# Template register map
Vendor: VendorName Co.Ltd; Series: SeriesName; File version: 1.2
CPU: CM7 r0p1, little endian, MPU, FPU, 4 interrupt priority bits
Registers are 32-bit, read-write, no defined reset value unless marked. A register's access mark holds for its fields unless they carry their own. Offsets are from the block's base; [hi:lo] are bit positions; lines under a group give offsets from that group; {n}, {i} and the like mark numbered series.

## CANFD1 — Controller Area Network FD 1
Base 0x40084000
Same registers: CANFD2 0x4009C000
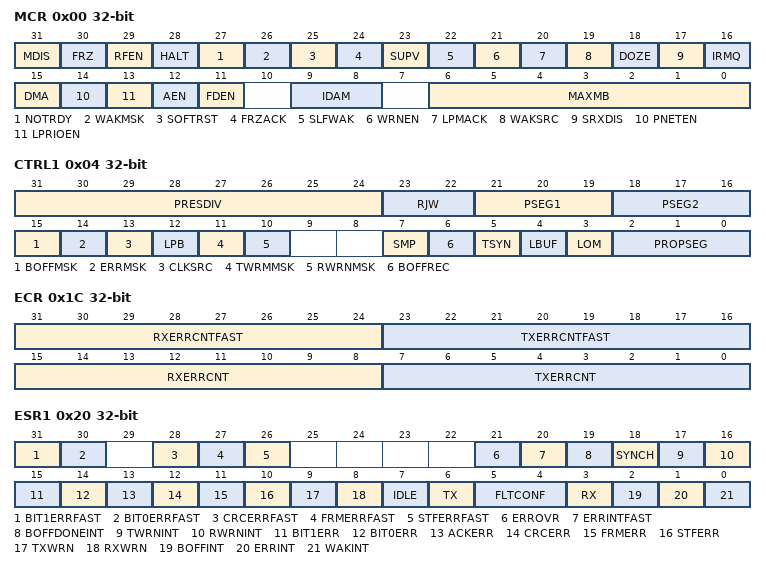
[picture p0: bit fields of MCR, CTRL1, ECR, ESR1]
0x00 MCR — CAN module config register
  [31] MDIS — CANFD MDIS bit: module disable
  [30] FRZ — CANFD FRZ bit: freeze enable
  [29] RFEN — CANFD RFEN bit: Rx FIFO enable
  [28] HALT — CANFD HALT bit: halt FlexCAN
  [27] NOTRDY — CANFD NOTRDY bit: FlexCAN not ready
  [26] WAKMSK — CANFD WAKMSK bit: wake up interrupt mask
  [25] SOFTRST — CANFD SOFTRST bit: soft reset
  [24] FRZACK ro — CANFD FRZACK bit: freeze mode acknowledge
  [23] SUPV — CANFD SUPV bit: supervisor mode
  [22] SLFWAK — CANFD SLFWAK bit: self wake up
  [21] WRNEN — CANFD WRNEN bit: warning interrupt enable
  [20] LPMACK — CANFD LPMACK bit: low-power mode acknowledge
  [19] WAKSRC — CANFD WAKSRC bit: wake up source
  [18] DOZE — CANFD DOZE bit: doze mode enable
  [17] SRXDIS — CANFD SRXDIS bit: self reception disable
  [16] IRMQ — CANFD IRMQ bit: individual Rx masking And queue enable
  [15] DMA — CANFD DMA bit: DMA enable
  [14] PNETEN — CANFD PNETEN bit: pretended networking enable
  [13] LPRIOEN — CANFD LPRIOEN bit: local priority enable
  [12] AEN — CANFD AEN bit: abort enable
  [11] FDEN — CANFD FDEN bit: CAN FD operation enable
  [9:8] IDAM — CANFD IDAM[1:0] bit: ID acceptance mode
  [6:0] MAXMB — CANFD MAXMB[6:0] bit: number of the last message buffer
0x04 CTRL1 — CAN control register 1
  [31:24] PRESDIV — CANFD PRESDIV[7:0] bit: prescaler division factor
  [23:22] RJW — CANFD RJW[1:0] bit: resync jump width
  [21:19] PSEG1 — CANFD PSEG1[2:0] bit: phase segment 1
  [18:16] PSEG2 — CANFD PSEG2[2:0] bit: phase segment 2
  [15] BOFFMSK — CANFD BOFFMSK bit: bus off interrtupt mask
  [14] ERRMSK — CANFD ERRMSK bit: error interrupt mask
  [13] CLKSRC — CANFD CLKSRC bit: CAN engine clock source
  [12] LPB — CANFD LPB bit: loop-back mode
  [11] TWRMMSK — CANFD TWRMMSK bit: Tx warning inrerrupt mask
  [10] RWRNMSK — CANFD RWRNMSK bit: Rx warn inrerrupt mask
  [7] SMP — CANFD SMP bit: CAN bit sampling
  [6] BOFFREC — CANFD BOFFREC bit: bus off recovery
  [5] TSYN — CANFD TSYN bit: timer sync
  [4] LBUF — CANFD LBUF bit: lowest buffer transmitted first
  [3] LOM — CANFD LOM bit: listen-only mode
  [2:0] PROPSEG — CANFD PROPSEG[2:0] bit: propagation segment
0x08 TIMER — CAN free-running timer register
  [15:0] TIMER — CANFD TIMER[15:0] bit: timer value
0x10 RXMGMASK — CAN receiving mailbox global mask register
  [31:0] MG — CANFD MG[31:0] bit: Rx mailboxes global mask bits
0x14 RX14MASK — CAN receiving buffer 14 mask register
  [31:0] RX14M — CANFD RX14M[31:0] bit: Rx buffer 14 mask bits
0x18 RX15MASK — CAN receiving buffer 15 mask register
  [31:0] RX15M — CANFD RX15M[31:0] bit: Rx buffer 15 mask bits
0x1C ECR — CAN error count register
  [31:24] RXERRCNTFAST ro — CANFD RXERRCNTFAST[7:0] bit: receive error counter for fast bits
  [23:16] TXERRCNTFAST ro — CANFD TXERRCNTFAST[7:0] bit: transmit error counter for fast bits
  [15:8] RXERRCNT — CANFD RXERRCNT[7:0] bit: receive error counter
  [7:0] TXERRCNT — CANFD TXERRCNT[7:0] bit: transmit error counter
0x20 ESR1 — CAN error and state register 1
  [31] BIT1ERRFAST ro — CANFD BIT1ERRFAST bit: bit1 error in the data phase of CAN FD frames with the BRS bit set
  [30] BIT0ERRFAST ro — CANFD BIT0ERRFAST bit: bit0 error in the data phase of CAN FD frames with the BRS bit set
  [28] CRCERRFAST ro — CANFD CRCERRFAST bit: cyclic redundancy check error in the CRC field of CAN FD frames with the BRS bit set
  [27] FRMERRFAST ro — CANFD FRMERRFAST bit: form error in the data phase of CAN FD frames with the BRS bit set
  [26] STFERRFAST ro — CANFD STFERRFAST bit: stuffing error in the data phase of CAN FD frames with the BRS bit set
  [21] ERROVR — CANFD ERROVR bit: error overrun
  [20] ERRINTFAST — CANFD ERRINTFAST bit: error interrupt for errors detected in the data phase of CAN FD frames with the BRS bit set
  [19] BOFFDONEINT — CANFD BOFFDONEINT bit: bus off done interrupt
  [18] SYNCH — CANFD SYNCH bit: CAN synchronization status
  [17] TWRNINT — CANFD TWRNINT bit: Tx warning interrupt flag
  [16] RWRNINT — CANFD RWRNINT bit: Rx warning interrupt flag
  [15] BIT1ERR ro — CANFD BIT1ERR bit: bit1 error
  [14] BIT0ERR ro — CANFD BIT0ERR bit: bit0 error
  [13] ACKERR ro — CANFD ACKERR bit: acknowledge error
  [12] CRCERR ro — CANFD CRCERR bit: cyclic redundancy check error
  [11] FRMERR ro — CANFD FRMERR bit: form error
  [10] STFERR ro — CANFD STFERR bit: stuffing error
  [9] TXWRN ro — CANFD TXWRN bit: Tx error warning
  [8] RXWRN ro — CANFD RXWRN bit: Rx error warning
  [7] IDLE ro — CANFD IDLE bit: idle state bit
  [6] TX ro — CANFD TX bit: FlexCAN in transmission
  [5:4] FLTCONF ro — CANFD FLTCONF[1:0] bit: fault confinement state
  [3] RX ro — CANFD RX bit: FlexCAN in reception
  [2] BOFFINT — CANFD BOFFINT bit: bus off interrupt
  [1] ERRINT — CANFD ERRINT bit: error interrupt
  [0] WAKINT — CANFD WAKINT bit: wake up interrupt
0x24 IMASK2 — CAN interrupt mask register 2
  [31:0] BUF63TO32M — CANFD BUF63TO32M[31:0] bit: buffer MB i mask 2
0x28 IMASK1 — CAN interrupt mask register 1
  [31:0] BUF31TO0M — CANFD BUF31TO0M[31:0] bit: buffer MB i mask 1
0x2C IFLAG2 — CAN interrupt flag register 2
  [31:0] BUF63TO32I — CANFD BUF63TO32I[31:0] bit: buffer MB i interrupt 2
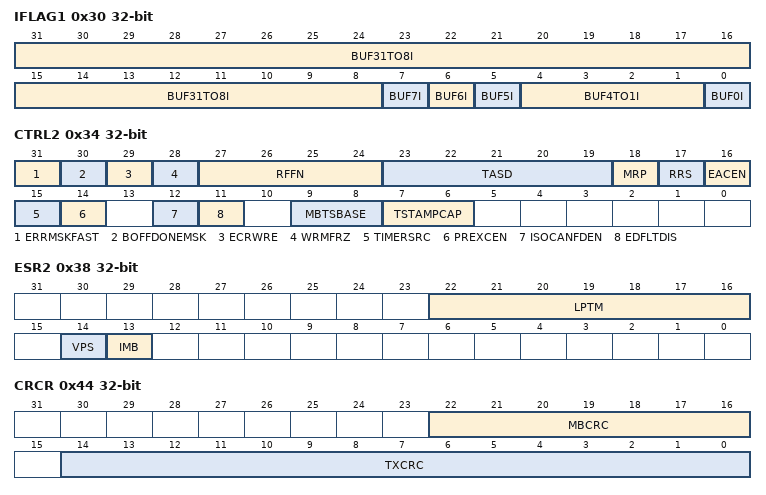
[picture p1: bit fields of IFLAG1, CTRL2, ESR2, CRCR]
0x30 IFLAG1 — CAN interrupt flag register 1
  [31:8] BUF31TO8I — CANFD BUF31TO8I[23:0] bit: buffer MB i interrupt 1
  [7] BUF7I — CANFD BUF7I bit: buffer MB7 interrupt or legacy Rx FIFO overflow
  [6] BUF6I — CANFD BUF6I bit: buffer MB6 interrupt or legacy Rx FIFO warning
  [5] BUF5I — CANFD BUF5I bit: buffer MB5 interrupt or frames available in legacy Rx FIFO
  [4:1] BUF4TO1I — CANFD BUF4TO1I[3:0] bit: buffer MB interrupt or reserved
  [0] BUF0I — CANFD BUF0I bit: buffer MB0 interrupt or clear legacy Rx FIFO bit
0x34 CTRL2 — CAN control register 2
  [31] ERRMSKFAST — CANFD ERRMSKFAST bit: error interrupt mask for errors detected in the data phase of fast CAN FD frames
  [30] BOFFDONEMSK — CANFD BOFFDONEMSK bit: bus off done interrupt mask
  [29] ECRWRE — CANFD ECRWRE bit: error-correction configuration register write enable
  [28] WRMFRZ — CANFD WRMFRZ bit: writing-access to memory in freeze mode
  [27:24] RFFN — CANFD RFFN[3:0] bit: number of legacy Rx FIFO filters
  [23:19] TASD — CANFD TASD[4:0] bit: Tx arbitration start delay
  [18] MRP — CANFD MRP bit: mailboxes reception priority
  [17] RRS — CANFD RRS bit: remote request storing
  [16] EACEN — CANFD EACEN bit: entire frame arbitration field comparison enable for Rx mailboxes
  [15] TIMERSRC — CANFD TIMERSRC bit: timer source
  [14] PREXCEN — CANFD PREXCEN bit: protocol exception enable
  [12] ISOCANFDEN — CANFD ISOCANFDEN bit: ISO CAN FD enable
  [11] EDFLTDIS — CANFD EDFLTDIS bit: edge filter disable
  [9:8] MBTSBASE — CANFD MBTSBASE[1:0] bit: message buffer time stamp base
  [7:6] TSTAMPCAP — CANFD TSTAMPCAP[1:0] bit: time stamp capture point
0x38 ESR2 ro — CAN error and state register 2
  [22:16] LPTM — CANFD LPTM[6:0] bit: lowest priority Tx mailbox
  [14] VPS — CANFD VPS bit: valid priority status
  [13] IMB — CANFD IMB bit: inactive mailbox
0x44 CRCR ro — CAN CRC register
  [22:16] MBCRC — CANFD MBCRC[6:0] bit: CRC mailbox
  [14:0] TXCRC — CANFD TXCRC[14:0] bit: transmitted CRC value
0x48 RXFGMASK — CAN receiving FIFO mailbox global mask register
  [31:0] FGM — CANFD FGM[31:0] bit: legacy Rx FIFO global mask bits
0x4C RXFIR ro — CAN receiving FIFO information register
  [8:0] IDHIT — CANFD IDHIT[8:0] bit: identifier acceptance filter hit indicator
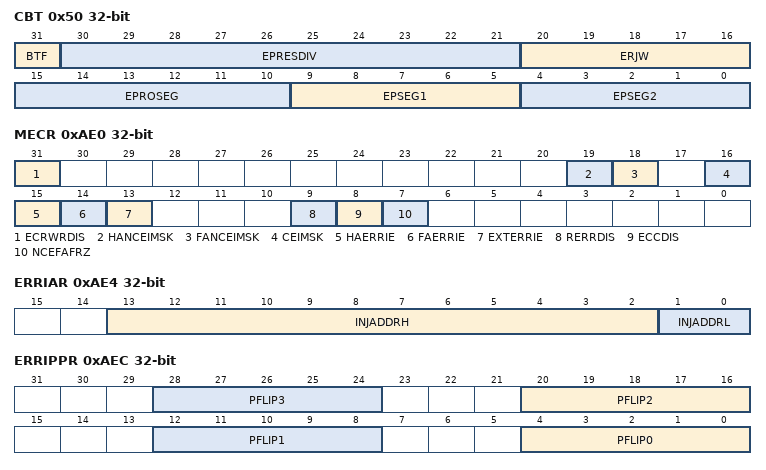
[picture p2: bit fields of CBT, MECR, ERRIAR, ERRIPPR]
0x50 CBT — CAN bits timer register
  [31] BTF — CANFD BTF bit: bit timing format enable
  [30:21] EPRESDIV — CANFD EPRESDIV[9:0] bit: extended prescaler division factor
  [20:16] ERJW — CANFD ERJW[4:0] bit: extended resync jump width
  [15:10] EPROSEG — CANFD EPROSEG[5:0] bit: extended propagation segment
  [9:5] EPSEG1 — CANFD EPSEG1[4:0] bit: extended phase segment 1
  [4:0] EPSEG2 — CANFD EPSEG2[4:0] bit: extended phase segment 2
0x68 IMASK4 — CAN interrupt mask register 4
  [31:0] BUF127TO96M — CANFD BUF127TO96M[31:0] bit: buffer MB i mask 4
0x6C IMASK3 — CAN interrupt mask register 3
  [31:0] BUF95TO64M — CANFD BUF95TO64M[31:0] bit: buffer MB i mask 3
0x70 IFLAG4 — CAN interrupt flag register 4
  [31:0] BUF127TO96I — CANFD BUF127TO96I[31:0] bit: buffer MB i interrupt 4
0x74 IFLAG3 — CAN interrupt flag register 3
  [31:0] BUF95TO64I — CANFD BUF95TO64I[31:0] bit: buffer MB i interrupt 3
0x7C GFWR — CAN glitch filter window register
  [7:0] GFWR — CANFD GFWR[7:0] bit: fault filter width
{0x880+4i} RXIMRX[{i}] (i=0..127) — Grouping of RXIMR0~RXIMR127
  [31:0] MI — CANFD MI[31:0] bit: individual mask bit x
0xAE0 MECR — CAN memory error control register
  [31] ECRWRDIS — CANFD ECRWRDIS bit: error configuration register write disable
  [19] HANCEIMSK — CANFD HANCEIMSK bit: host access with non-correctable errors interrupt mask
  [18] FANCEIMSK — CANFD FANCEIMSK bit: FlexCAN access with non-correctable errors interrupt mask
  [16] CEIMSK — CANFD CEIMSK bit: correctable errors interrupt mask
  [15] HAERRIE — CANFD HAERRIE bit: host access error injection enable
  [14] FAERRIE — CANFD FAERRIE bit: FlexCAN access error injection enable
  [13] EXTERRIE — CANFD EXTERRIE bit: extended error injection enable
  [9] RERRDIS — CANFD RERRDIS bit: error report disable
  [8] ECCDIS — CANFD ECCDIS bit: error correction disable
  [7] NCEFAFRZ — CANFD NCEFAFRZ bit: non-correctable errors in FlexCAN access put device in freeze mode
0xAE4 ERRIAR — CAN input address error register
  [13:2] INJADDRH — CANFD INJADDRH[11:0] bit: error injection address high
  [1:0] INJADDRL ro — CANFD INJADDRL[1:0] bit: error injection address low
0xAE8 ERRIDPR — CAN input data error register
  [31:0] DFLIP — CANFD DFLIP[31:0] bit: data flip pattern
0xAEC ERRIPPR — CAN input parity check error register
  [8n+4:8n] PFLIP{n} (n=0..3) — CANFD PFLIP{n}[4:0] bit: parity flip pattern for byte {n}
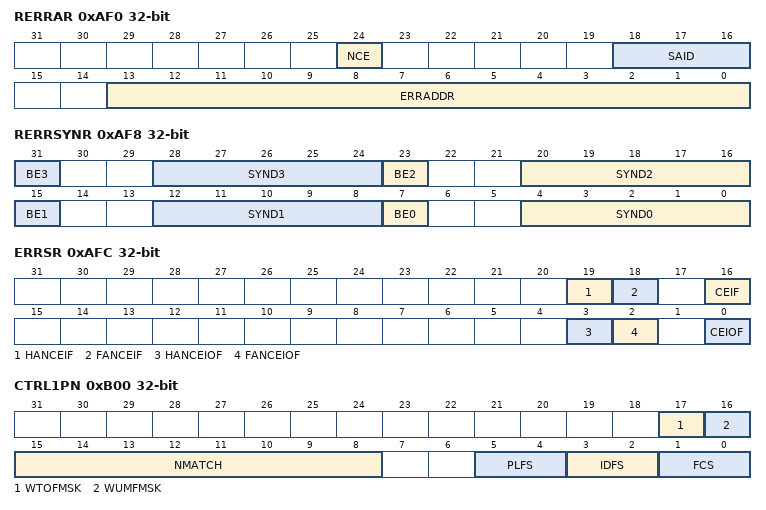
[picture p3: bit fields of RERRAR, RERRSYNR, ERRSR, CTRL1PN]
0xAF0 RERRAR ro — CAN report error address register
  [24] NCE — CANFD NCE bit: non-correctable error
  [18:16] SAID — CANFD SAID[2:0] bit: SAID mode enable
  [13:0] ERRADDR — CANFD ERRADDR[13:0] bit: address where the error was detected
0xAF4 RERRDR ro — CAN report error data register
  [31:0] RDATA — CANFD RDATA[31:0] bit: raw data word read from memory with error
0xAF8 RERRSYNR ro — CAN report error synthesis register
  [8n+7] BE{n} (n=0..3) — CANFD BE{n} bit: byte enabled for byte {n}
  [8n+4:8n] SYND{n} (n=0..3) — CANFD SYND{n}[4:0] bit: error syndrome for byte {n}
0xAFC ERRSR — CAN error state register
  [19] HANCEIF — CANFD HANCEIF bit: host access with non-correctable error interrupt flag
  [18] FANCEIF — CANFD FANCEIF bit: FlexCAN access with non-correctable error interrupt flag
  [16] CEIF — CANFD CEIF bit: correctable error interrupt flag
  [3] HANCEIOF — CANFD HANCEIOF bit: host access with non-correctable error interrupt overrun flag
  [2] FANCEIOF — CANFD FANCEIOF bit: FlexCAN access with non-correctable error interrupt overrun flag
  [0] CEIOF — CANFD CEIOF bit: correctable error interrupt overrun flag
0xB00 CTRL1PN — CAN PN control register 1
  [17] WTOFMSK — CANFD WTOFMSK bit: wake up by timeout flag mask bit
  [16] WUMFMSK — CANFD WUMFMSK bit: wake up by match flag mask bit
  [15:8] NMATCH — CANFD NMATCH[7:0] bit: match message number with same filtering conditions
  [5:4] PLFS — CANFD PLFS[1:0] bit: payload filtering selection
  [3:2] IDFS — CANFD IDFS[1:0] bit: ID filtering selection
  [1:0] FCS — CANFD FCS[1:0] bit: filtering combination selection
0xB04 CTRL2PN — CAN PN control register 2
  [15:0] MATCHTO — CANFD MATCHTO[15:0] bit: match and define a timeout value
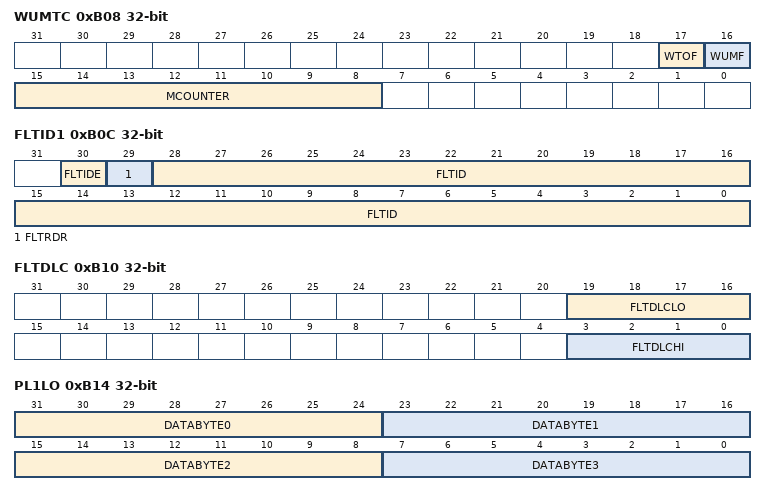
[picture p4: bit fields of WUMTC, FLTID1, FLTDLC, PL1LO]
0xB08 WUMTC — CAN PN wakeup and match register
  [17] WTOF — CANFD WTOF bit: wake up by timeout flag bit
  [16] WUMF — CANFD WUMF bit: wake up by match flag bit
  [15:8] MCOUNTER ro — CANFD MCOUNTER[7:0] bit: number of matches while in pretended networking
0xB0C FLTID1 — CAN PN ID filter register
  [30] FLTIDE — CANFD FLTIDE bit: ID extended filter
  [29] FLTRDR — CANFD FLTRDR bit: remote transmission request filter
  [28:0] FLTID — CANFD FLTID[28:0] bit: ID filter 1 for pretended networking filtering
0xB10 FLTDLC — CAN PN DLC filter register
  [19:16] FLTDLCLO — CANFD FLTDLCLO[3:0] bit: lower limit for length of data bytes filter
  [3:0] FLTDLCHI — CANFD FLTDLCHI[3:0] bit: upper limit for length of data bytes filter
0xB14 PL1LO — CAN PN PAYLOAD low filter register
  [31-8n:24-8n] DATABYTE{n} (n=0..3) — CANFD DATABYTE{n}[7:0] bit: payload filter 1 low order bits {n}
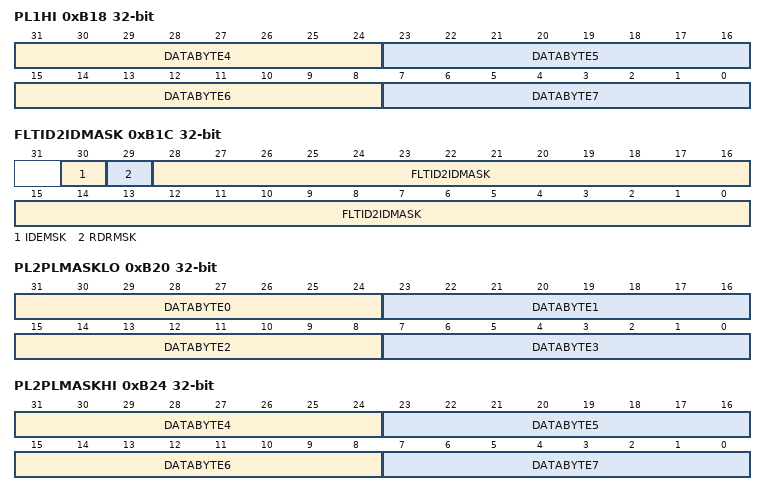
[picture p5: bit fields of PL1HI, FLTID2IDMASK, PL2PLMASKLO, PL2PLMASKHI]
0xB18 PL1HI — CAN PN PAYLOAD high filter register
  [63-8n:56-8n] DATABYTE{n} (n=4..7) — CANFD DATABYTE{n}[7:0] bit: payload filter 1 low order bits {n}
0xB1C FLTID2IDMASK — CAN PN ID filter mask register
  [30] IDEMSK — CANFD IDEMSK bit: ID extended mask bit
  [29] RDRMSK — CANFD RDRMSK bit: remote transmission request mask bit
  [28:0] FLTID2IDMASK — CANFD FLTID2IDMASK[28:0] bit: ID filter 2 pretended networking filtering
0xB20 PL2PLMASKLO — CAN PN PAYLOAD low filter mask register
  [31-8n:24-8n] DATABYTE{n} (n=0..3) — CANFD DATABYTE{n}[7:0] bit: payload filter 2 low order bits {n}
0xB24 PL2PLMASKHI — CAN PN PAYLOAD high filter mask register
  [63-8n:56-8n] DATABYTE{n} (n=4..7) — CANFD DATABYTE{n}[7:0] bit: payload filter 2 low order bits {n}
{0xB40+0x10*i} WMBX[{i}] (i=0..3) group — Grouping of WMB0CS/ID/D03/D47~WMB3CS/ID/D03/D47
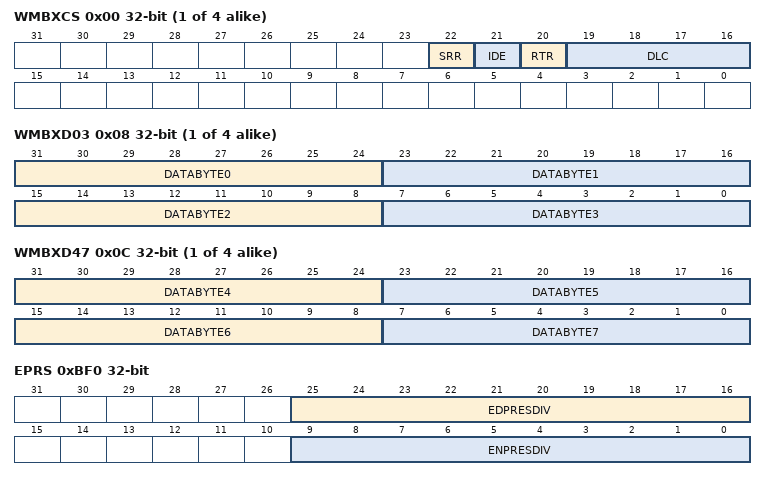
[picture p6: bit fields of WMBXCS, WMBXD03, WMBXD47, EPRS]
  0x00 WMBXCS ro — CAN wakeup message buffer x CS register
    [22] SRR — CANFD SRR bit: substitute remote request x
    [21] IDE — CANFD IDE bit: ID extended bit x
    [20] RTR — CANFD RTR bit: remote transmission request bit x
    [19:16] DLC — CANFD DLC[3:0] bit: length of data in bytes x
  0x04 WMBXID ro — CAN wakeup message buffer x ID register
    [28:0] ID — CANFD ID[28:0] bit: received ID under pretended networking mode x
  0x08 WMBXD03 ro — CAN wakeup message buffer x DATA0~3 register
    [31-8n:24-8n] DATABYTE{n} (n=0..3) — CANFD DATABYTE{n}[7:0] bit: receive payload corresponding to data byte {n} x
  0x0C WMBXD47 ro — CAN wakeup message buffer x DATA4~7 register
    [63-8n:56-8n] DATABYTE{n} (n=4..7) — CANFD DATABYTE{n}[7:0] bit: receive payload corresponding to data byte {n} x
0xBF0 EPRS — CAN enhanced bit time prescaling register
  [25:16] EDPRESDIV — CANFD EDPRESDIV[9:0] bit: extended data phase prediction calculator division factor
  [9:0] ENPRESDIV — CANFD ENPRESDIV[9:0] bit: extended nominal phase prediction calculator division factor
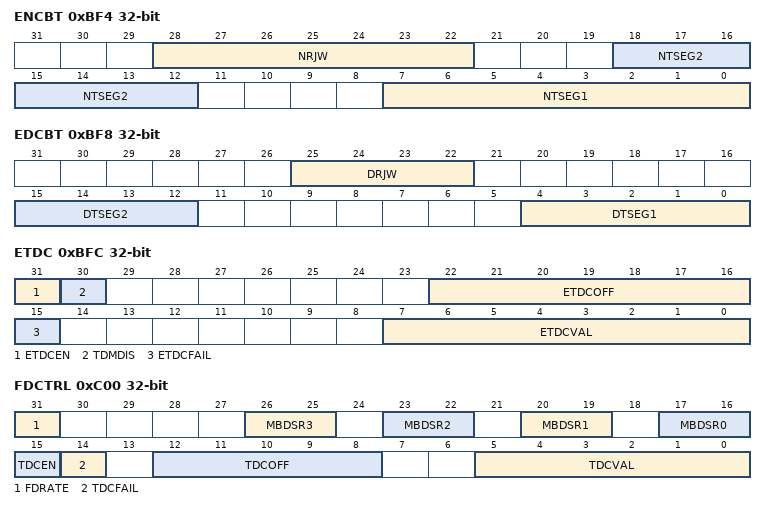
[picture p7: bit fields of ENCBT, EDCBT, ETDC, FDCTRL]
0xBF4 ENCBT — CAN enhanced nominal segment bit register
  [28:22] NRJW — CANFD NRJW[6:0] bit: nominal re-synchronization jump width
  [18:12] NTSEG2 — CANFD NTSEG2[6:0] bit: nominal time period 2
  [7:0] NTSEG1 — CANFD NTSEG1[7:0] bit: nominal time period 1
0xBF8 EDCBT — CAN enhanced data segment bit register
  [25:22] DRJW — CANFD DRJW[3:0] bit: data phase re-synchronization jump width
  [15:12] DTSEG2 — CANFD DTSEG2[3:0] bit: data phase time period 2
  [4:0] DTSEG1 — CANFD DTSEG1[4:0] bit: data phase time period 1
0xBFC ETDC — CAN enhanced rx/tx delay calibration register
  [31] ETDCEN — CANFD ETDCEN bit: receiver delay compensation enable
  [30] TDMDIS — CANFD TDMDIS bit: receiver delay measurement invalid
  [22:16] ETDCOFF — CANFD ETDCOFF[6:0] bit: receiver delay compensation offset
  [15] ETDCFAIL — CANFD ETDCFAIL bit: receiver delay compensation fail
  [7:0] ETDCVAL ro — CANFD ETDCVAL[7:0] bit: receiver delay compensation value
0xC00 FDCTRL — CAN FD control register
  [31] FDRATE — CANFD FDRATE bit: bit rate switch enable
  [3n+17:3n+16] MBDSR{n} (n=0..3) — CANFD MBDSR{n}[1:0] bit: message buffer data size of region {n}
  [15] TDCEN — CANFD TDCEN bit: transceiver delay compensation enable
  [14] TDCFAIL — CANFD TDCFAIL bit: transceiver delay compensation fail
  [12:8] TDCOFF — CANFD TDCOFF[4:0] bit: transceiver delay compensation offset
  [5:0] TDCVAL ro — CANFD TDCVAL[5:0] bit: transceiver sdelay compensation value
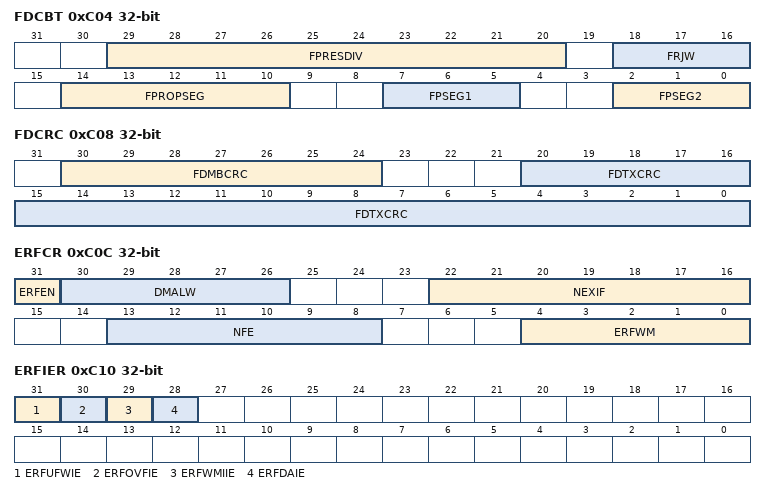
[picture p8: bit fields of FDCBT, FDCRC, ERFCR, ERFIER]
0xC04 FDCBT — CAN FD bits timer register
  [29:20] FPRESDIV — CANFD FPRESDIV[9:0] bit: fast prescaler division factor
  [18:16] FRJW — CANFD FRJW[2:0] bit: fast resync jump width
  [14:10] FPROPSEG — CANFD FPROPSEG[4:0] bit: fast propagation segment
  [7:5] FPSEG1 — CANFD FPSEG1[2:0] bit: fast phase segment 1
  [2:0] FPSEG2 — CANFD FPSEG2[2:0] bit: fast phase segment 2
0xC08 FDCRC ro — CAN FD CRC register
  [30:24] FDMBCRC — CANFD FDMBCRC[6:0] bit: CRC mailbox number for FDTXCRC
  [20:0] FDTXCRC — CANFD FDTXCRC[20:0] bit: extended transmitted CRC value
0xC0C ERFCR — CAN enhanced receiving FIFO control register
  [31] ERFEN — CANFD ERFEN bit: enhanced Rx FIFO enable
  [30:26] DMALW — CANFD DMALW[4:0] bit: DMA last word
  [22:16] NEXIF — CANFD NEXIF[6:0] bit: number of extended ID filter elements
  [13:8] NFE — CANFD NFE[5:0] bit: number of enhanced Rx FIFO filter elements
  [4:0] ERFWM — CANFD ERFWM[4:0] bit: enhanced Rx FIFO watermark
0xC10 ERFIER — CAN enhanced receiving FIFO interrupt enable register
  [31] ERFUFWIE — CANFD ERFUFWIE bit: enhanced Rx FIFO underflow interrupt enable
  [30] ERFOVFIE — CANFD ERFOVFIE bit: enhanced Rx FIFO overflow interrupt enable
  [29] ERFWMIIE — CANFD ERFWMIIE bit: enhanced Rx FIFO watermark indication interrupt enable
  [28] ERFDAIE — CANFD ERFDAIE bit: enhanced Rx FIFO data available interrupt enable
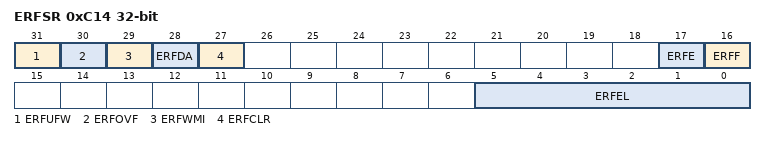
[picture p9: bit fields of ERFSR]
0xC14 ERFSR — CAN enhanced receiving FIFO state register
  [31] ERFUFW — CANFD ERFUFW bit: enhanced Rx FIFO underflow
  [30] ERFOVF — CANFD ERFOVF bit: enhanced Rx FIFO overflow
  [29] ERFWMI — CANFD ERFWMI bit: enhanced Rx FIFO watermark indication
  [28] ERFDA — CANFD ERFDA bit: enhanced Rx FIFO data available
  [27] ERFCLR wo — CANFD ERFCLR bit: enhanced Rx FIFO clear
  [17] ERFE ro — CANFD ERFE bit: enhanced Rx FIFO empty
  [16] ERFF ro — CANFD ERFF bit: enhanced Rx FIFO full
  [5:0] ERFEL ro — CANFD ERFEL[5:0] bit: enhanced Rx FIFO elements
{0xC30+4i} HRTIMESTAMPX[{i}] (i=0..127) — Grouping of HRTIMESTAMP0~HRTIMESTAMP127
  [31:0] TS — CANFD TS[31:0] bit: high resolution timestamp
{0x3000+4i} ERFFELX[{i}] (i=0..127) — Grouping of ERFFEL0~ERFFEL127
  [31:0] FEL — CANFD FEL[31:0] bit: filter element bits x
